AUTOSAR XML (schema 00049)
package /AppDesign
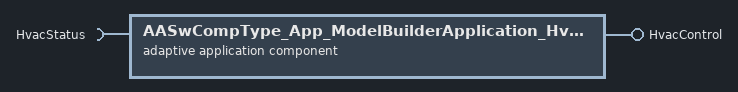
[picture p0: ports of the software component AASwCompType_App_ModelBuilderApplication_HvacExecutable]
  adaptive application sw component type AASwCompType_App_ModelBuilderApplication_HvacExecutable
    provide port HvacControl: provided-interface=HvacControl
    require port HvacStatus: required-interface=HvacStatus
  executable HvacExecutable: category=APPLICATION_LEVEL, version=1.0.0
    root sw component prototype RootSwcPrototype: application-type=AASwCompType_App_ModelBuilderApplication_HvacExecutable
  process design PrcDesign_App_ModelBuilderApplication_HvacExecutable: executable=HvacExecutable
  software cluster design SwClDesign_App_ModelBuilderApplication: contained-process=PrcDesign_App_ModelBuilderApplication_HvacExecutable
